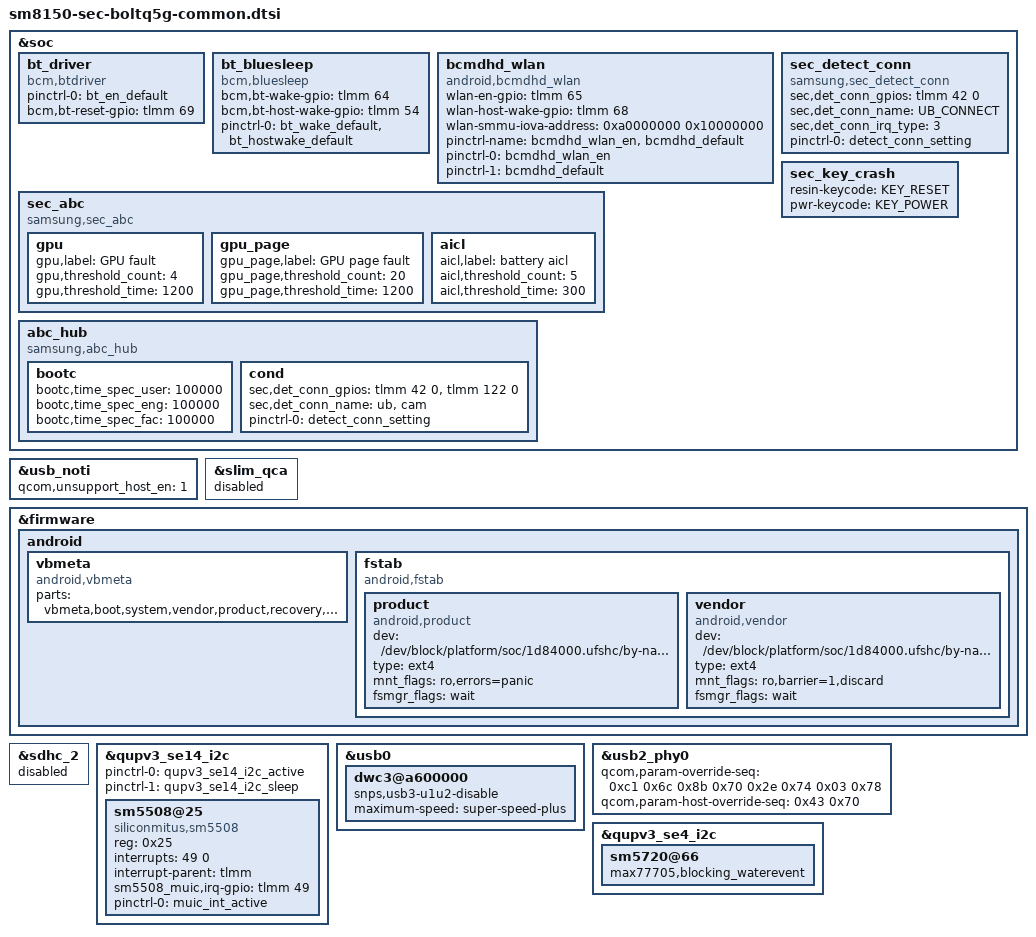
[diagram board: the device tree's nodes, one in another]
/* Copyright (c) 2016-2017, The Linux Foundation. All rights reserved.
 *
 * This program is free software; you can redistribute it and/or modify
 * it under the terms of the GNU General Public License version 2 and
 * only version 2 as published by the Free Software Foundation.
 *
 * This program is distributed in the hope that it will be useful,
 * but WITHOUT ANY WARRANTY; without even the implied warranty of
 * MERCHANTABILITY or FITNESS FOR A PARTICULAR PURPOSE.  See the
 * GNU General Public License for more details.
 */

#include "sm8150-sec-boltq5g-audio.dtsi"

&soc {
	bt_driver {
		compatible = "bcm,btdriver";  //bt_en
		pinctrl-names = "default";
		pinctrl-0 = <&bt_en_default>;
		bcm,bt-reset-gpio = <&tlmm 69 GPIO_ACTIVE_HIGH>;
		status = "okay";
	};

	bt_bluesleep {
		compatible = "bcm,bluesleep";
		bcm,bt-wake-gpio = <&tlmm 64 0>;
		bcm,bt-host-wake-gpio = <&tlmm 54 0>;
		pinctrl-names = "default";
		pinctrl-0 = <&bt_wake_default &bt_hostwake_default>;
		status = "okay";
	};

       bcmdhd_wlan {
		 compatible = "android,bcmdhd_wlan";
		 wlan-en-gpio = <&tlmm 65 0>;
		 wlan-host-wake-gpio = <&tlmm 68 0>;
		 wlan-smmu-iova-address = <0xa0000000 0x10000000>;
		 pinctrl-name = "bcmdhd_wlan_en","bcmdhd_default";
		 pinctrl-0 = <&bcmdhd_wlan_en>;
		 pinctrl-1 = <&bcmdhd_default>;
		 status = "ok";
	};

	sec_detect_conn {
		compatible = "samsung,sec_detect_conn";
		sec,det_conn_gpios = <&tlmm 42 0>; /* UB_CON_DETECT */

		sec,det_conn_name = "UB_CONNECT";

		sec,det_conn_irq_type = <3>; /* UB_CON_DETECT FALLING, RIGING EDGE*/

		pinctrl-names = "det_ap_connect";
		pinctrl-0 = <&detect_conn_setting>;
	};

	sec_abc {
		compatible = "samsung,sec_abc";
		status = "okay";

		gpu {
			gpu,label="GPU fault";
			gpu,threshold_count=<4>;
			gpu,threshold_time=<1200>;
		};
		gpu_page {
			gpu_page,label="GPU page fault";
			gpu_page,threshold_count=<20>;
			gpu_page,threshold_time=<1200>;
		};
		aicl {
			aicl,label="battery aicl";
			aicl,threshold_count=<5>;
			aicl,threshold_time=<300>;
		};
	};

	abc_hub {
		compatible = "samsung,abc_hub";
		status = "okay";

		bootc {
			bootc,time_spec_user = <100000>; /* user binary user build */
			bootc,time_spec_eng = <100000>; /* user binary eng build */
			bootc,time_spec_fac = <100000>; /* factory binary */
		};

		cond {
			sec,det_conn_gpios = <&tlmm 42 0 /* UB_CON_DETECT */
						&tlmm 122 0>; /* CAM_DETECT */
			sec,det_conn_name = "ub", "cam";
			pinctrl-names = "det_ap_connect";
			pinctrl-0 = <&detect_conn_setting>;
		};
	};

	sec_key_crash {
		resin-keycode = <KEY_RESET>;
		pwr-keycode = <KEY_POWER>;
	};
};

&usb_noti {	
	qcom,unsupport_host_en = <1>;
};

&slim_qca {
	status = "disabled";
};

&firmware {
	android {
		vbmeta {
			compatible = "android,vbmeta";
			parts = "vbmeta,boot,system,vendor,product,recovery,dtbo,abl,xbl,tz,hyp";
		};
		fstab {
			compatible = "android,fstab";
			product {
				compatible = "android,product";
				/* dev = "/dev/block/bootdevice/by-name/product"; */
				dev = "/dev/block/platform/soc/1d84000.ufshc/by-name/product";
				type = "ext4";
				mnt_flags = "ro,errors=panic";
				fsmgr_flags = "wait";
			};
			vendor {
				compatible = "android,vendor";
				/*dev = "/dev/block/bootdevice/by-name/vendor";*/
				dev = "/dev/block/platform/soc/1d84000.ufshc/by-name/vendor";
				type = "ext4";
				mnt_flags = "ro,barrier=1,discard";
				fsmgr_flags = "wait";
			};
		};
	};
};

&sdhc_2 {
	status = "disabled";
};

&qupv3_se14_i2c {
	status = "ok";

	pinctrl-names = "default", "sleep";
	pinctrl-0 = <&qupv3_se14_i2c_active>;
	pinctrl-1 = <&qupv3_se14_i2c_sleep>;

	sm5508@25 {
		compatible = "siliconmitus,sm5508";
		reg = <0x25>;
		interrupts = <49 0>;
		interrupt-parent = <&tlmm>;
//		sm5508_muic,gpio-scl = 
//		sm5508_muic,gpio-sda = 
		sm5508_muic,irq-gpio = <&tlmm 49 0x00>;
		pinctrl-names = "default";
		pinctrl-0 = <&muic_int_active>;
	};
};

&usb0 {
	dwc3@a600000 {
		snps,usb3-u1u2-disable;
		maximum-speed = "super-speed-plus";
	};
};

&usb2_phy0 {
	qcom,param-override-seq =
		<0xc1 0x6c
		 0x8b 0x70
		 0x2e 0x74
		 0x03 0x78>;
	qcom,param-host-override-seq =
		<0x43 0x70>;
};

&qupv3_se4_i2c {
	sm5720@66 {
			max77705,blocking_waterevent;
	};
};
